VERSION ""

NS_ :

BS_:

BU_: PLEX

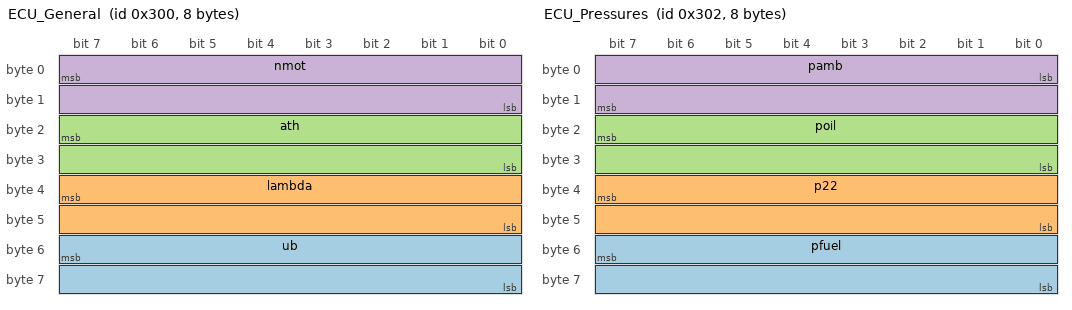
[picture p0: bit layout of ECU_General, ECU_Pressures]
BO_ 768 ECU_General: 8 MS6_Logger_CAN_Bus_1
 SG_ ub : 55|16@0- (0.01,0) [0|25.5] "V" Vector__XXX
 SG_ lambda : 39|16@0- (0.001,0) [0|5] "" Vector__XXX
 SG_ ath : 23|16@0- (0.1,0) [0|110] "%" Vector__XXX
 SG_ nmot : 7|16@0- (1,0) [0|20000] "rpm" Vector__XXX

BO_ 770 ECU_Pressures: 8 MS6_Logger_CAN_Bus_1
 SG_ pfuel : 55|16@0- (0.001,0) [0|10] "bar" Vector__XXX
 SG_ p22 : 39|16@0- (1,0) [0|5000] "mbar" Vector__XXX
 SG_ poil : 23|16@0- (0.001,0) [0|10] "bar" Vector__XXX
 SG_ pamb : 0|16@1+ (0.1,0) [0|2000] "mbar" Vector__XXX

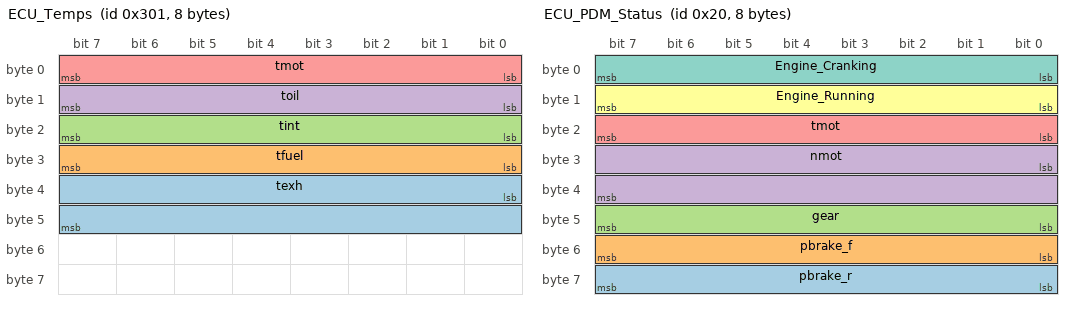
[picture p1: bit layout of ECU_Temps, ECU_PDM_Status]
BO_ 769 ECU_Temps: 8 MS6_Logger_CAN_Bus_1
 SG_ texh : 32|16@1+ (1,0) [0|1250] "°C" Vector__XXX
 SG_ tfuel : 31|8@0+ (1,0) [10|80] "°C" Vector__XXX
 SG_ tint : 23|8@0+ (1,0) [10|60] "°C" Vector__XXX
 SG_ toil : 15|8@0+ (1,0) [60|150] "°C" Vector__XXX
 SG_ tmot : 0|8@1+ (1,0) [40|120] "°C" Vector__XXX

BO_ 32 ECU_PDM_Status: 8 MS6_Logger_CAN_Bus_1
 SG_ pbrake_r : 56|8@1+ (1,0) [0|150] "bar" Vector__XXX
 SG_ pbrake_f : 48|8@1+ (1,0) [0|150] "bar" Vector__XXX
 SG_ gear : 40|8@1- (1,0) [-1|12] "" Vector__XXX
 SG_ nmot : 24|16@1+ (1,0) [0|20000] "rpm" Vector__XXX
 SG_ tmot : 16|8@1+ (1,0) [40|120] "°C" Vector__XXX
 SG_ Engine_Running : 8|8@1+ (1,0) [0|1] "" Vector__XXX
 SG_ Engine_Cranking : 0|8@1+ (1,0) [0|1] "" Vector__XXX

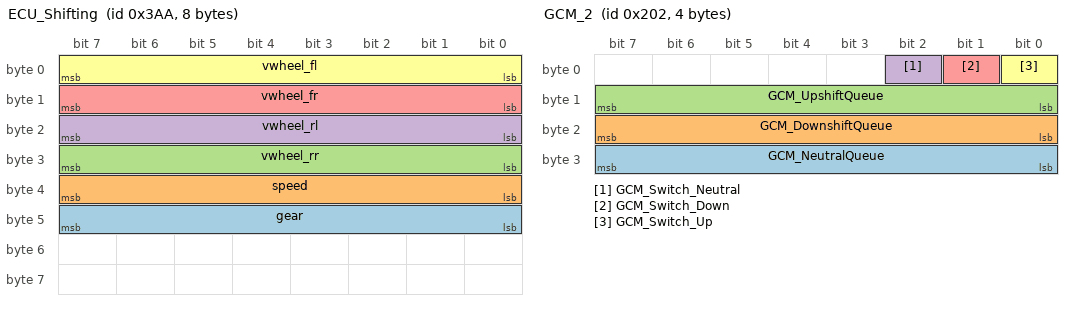
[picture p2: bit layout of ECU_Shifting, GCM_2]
BO_ 938 ECU_Shifting: 8 MS6_Logger_CAN_Bus_1
 SG_ gear : 40|8@1- (1,0) [-1|12] "" Vector__XXX
 SG_ speed : 32|8@1+ (1,0) [0|400] "km/h" Vector__XXX
 SG_ vwheel_rr : 24|8@1+ (1,0) [0|400] "km/h" Vector__XXX
 SG_ vwheel_rl : 16|8@1+ (1,0) [0|400] "km/h" Vector__XXX
 SG_ vwheel_fr : 8|8@1+ (1,0) [0|400] "km/h" Vector__XXX
 SG_ vwheel_fl : 0|8@1+ (1,0) [0|400] "km/h" Vector__XXX

BO_ 1023 ECU_Error: 8 MS6_Logger_CAN_Bus_1
 SG_ E_pbrake_f : 3|3@1+ (1,0) [0|255] "" Vector__XXX
 SG_ E_pbrake_r : 0|3@1+ (1,0) [0|255] "" Vector__XXX

BO_ 1967 IZZE_Brake_IR_Programming: 8 MS6_Logger_CAN_Bus_2

BO_ 256 GCM_MS6_Gear: 8 GCM
 SG_ GCM_Gear_MS6 : 0|8@1+ (0.5,-1.5) [0|0] "" Vector__XXX

BO_ 1552 GCM_MS6_Shift: 8 GCM
 SG_ GCM_Upshift_Bosch : 1|1@1+ (1,0) [0|0] "" Vector__XXX
 SG_ GCM_Downshift_Bosch : 0|1@1+ (1,0) [0|0] "" Vector__XXX

BO_ 514 GCM_2: 4 GCM
 SG_ GCM_NeutralQueue : 24|8@1+ (1,0) [0|0] "" Vector__XXX
 SG_ GCM_DownshiftQueue : 16|8@1+ (1,0) [0|0] "" Vector__XXX
 SG_ GCM_UpshiftQueue : 8|8@1+ (1,0) [0|0] "" Vector__XXX
 SG_ GCM_Switch_Neutral : 2|1@1+ (1,0) [0|0] "" Vector__XXX
 SG_ GCM_Switch_Down : 1|1@1+ (1,0) [0|0] "" Vector__XXX
 SG_ GCM_Switch_Up : 0|1@1+ (1,0) [0|0] "" Vector__XXX

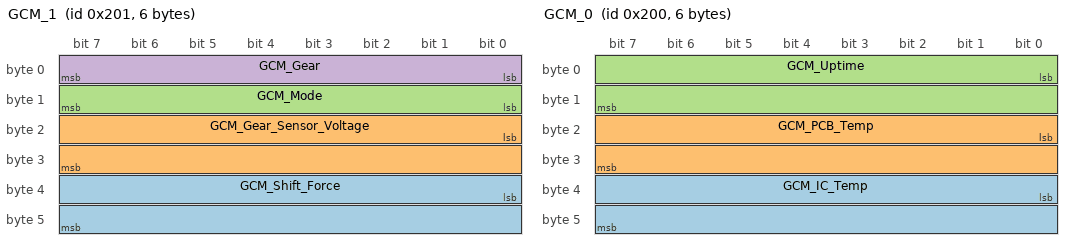
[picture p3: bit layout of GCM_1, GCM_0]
BO_ 513 GCM_1: 6 GCM
 SG_ GCM_Shift_Force : 32|16@1- (0.01,0) [0|0] "N" Vector__XXX
 SG_ GCM_Gear_Sensor_Voltage : 16|16@1+ (0.0001,0) [0|0] "V" Vector__XXX
 SG_ GCM_Mode : 8|8@1+ (1,0) [0|0] "" Vector__XXX
 SG_ GCM_Gear : 0|8@1+ (1,0) [0|0] "" Vector__XXX

BO_ 15 GCM_ERR: 4 GCM
 SG_ GCM_ERR_Code : 16|16@1+ (1,0) [0|0] "" Vector__XXX
 SG_ GCM_ERR_Origin_Node : 0|16@1+ (1,0) [0|0] "" Vector__XXX

BO_ 512 GCM_0: 6 GCM
 SG_ GCM_IC_Temp : 32|16@1- (0.005,0) [0|0] "C" Vector__XXX
 SG_ GCM_PCB_Temp : 16|16@1- (0.005,0) [0|0] "C" Vector__XXX
 SG_ GCM_Uptime : 0|16@1+ (1,0) [0|0] "s" Vector__XXX

BO_ 380 IMU_Z: 8 IMU
 SG_ IMU_Z_Accel : 32|16@1+ (0.0001274,-4.1746432) [0|0] "g" Vector__XXX

BO_ 376 IMU_X_Roll: 8 IMU
 SG_ IMU_X_Accel : 32|16@1+ (0.0001274,-4.1746432) [0|0] "g" Vector__XXX
 SG_ IMU_Roll_Rate : 0|16@1+ (0.005,-163.84) [0|0] "deg/s/s" Vector__XXX

BO_ 372 IMU_Y_Yaw: 8 IMU
 SG_ IMU_Y_Accel : 32|16@1+ (0.0001274,-4.1746432) [0|0] "g" Vector__XXX
 SG_ IMU_Yaw_Rate : 0|16@1+ (0.005,-163.84) [0|0] "deg/s" Vector__XXX

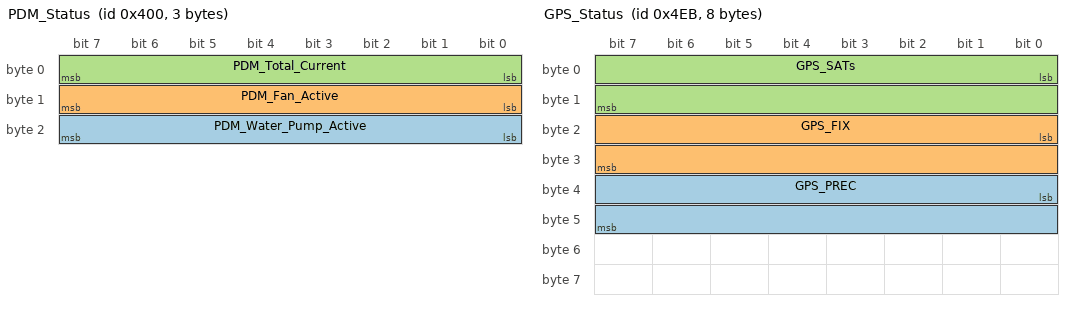
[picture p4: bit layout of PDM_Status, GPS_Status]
BO_ 1024 PDM_Status: 3 PDM
 SG_ PDM_Water_Pump_Active : 16|8@1- (1,0) [0|0] "" Vector__XXX
 SG_ PDM_Fan_Active : 8|8@1- (1,0) [0|0] "" Vector__XXX
 SG_ PDM_Total_Current : 0|8@1- (1,0) [0|127] "" Vector__XXX

BO_ 1259 GPS_Status: 8 PLEX
 SG_ GPS_PREC : 32|16@1- (0.1,0) [0|0] "m" Vector__XXX
 SG_ GPS_FIX : 16|16@1- (1,0) [0|0] "" Vector__XXX
 SG_ GPS_SATs : 0|16@1- (1,0) [0|0] "" Vector__XXX

BO_ 1258 GPS_Position: 8 PLEX
 SG_ GPS_Long : 32|32@1- (1e-07,0) [0|0] "deg" Vector__XXX
 SG_ GPS_Lat : 0|32@1- (1e-07,0) [0|0] "deg" Vector__XXX

CM_ BO_ 768 "RPM, Throttle Position, Lambda, Battery Voltage";
CM_ SG_ 768 ub "battery voltage";
CM_ SG_ 768 lambda "Lambda actual value";
CM_ SG_ 768 ath "throttle position";
CM_ SG_ 768 nmot "engine speed";
CM_ BO_ 770 "Ambient Pressure, Oil Pressure, Manifold Pressure, Fuel Pressure";
CM_ SG_ 770 pfuel "fuel pressure";
CM_ SG_ 770 p22 "intake manifold pressure downstream throttle";
CM_ SG_ 770 poil "oil pressure";
CM_ SG_ 770 pamb "ambient pressure";
CM_ BO_ 769 "Coolant Temp, Oil Temp, Manifold Temp, Fuel Temp, Exhaust Temp";
CM_ SG_ 769 texh "exhaust gas temperature";
CM_ SG_ 769 tfuel "fuel temperature";
CM_ SG_ 769 tint "intake air temperature";
CM_ SG_ 769 toil "oil temperature";
CM_ SG_ 769 tmot "engine temperature";
CM_ BO_ 32 "Engine_Cranking, Engine_Running, tmot, nmot, gear, pbrake_f, pbrake_r";
CM_ SG_ 32 pbrake_r "brake pressure rear";
CM_ SG_ 32 pbrake_f "brake pressure front ";
CM_ SG_ 32 gear "selected gear";
CM_ SG_ 32 nmot "engine speed";
CM_ SG_ 32 tmot "engine temperature";
CM_ SG_ 32 Engine_Running "Returns true, if (nmot > 0)";
CM_ SG_ 32 Engine_Cranking "Returns true, if (1 <= nmot <= 1000)";
CM_ BO_ 938 "FL/FR/RL/RR Wheel Speed, Ground Speed, Gear";
CM_ SG_ 938 gear "selected gear";
CM_ SG_ 938 speed "car speed";
CM_ SG_ 938 vwheel_rr "wheel speed rear right";
CM_ SG_ 938 vwheel_rl "wheel speed rear left";
CM_ SG_ 938 vwheel_fr "wheel speed front right";
CM_ SG_ 938 vwheel_fl "wheel speed front left";
CM_ BO_ 1023 "Critical error codes";
CM_ SG_ 1023 E_pbrake_f "error state brake pressure front";
CM_ SG_ 1023 E_pbrake_r "error state brake pressure rear";
CM_ BO_ 1967 "Programming message template for IZZE Brake IR sensor";
CM_ BO_ 1552 "Upshift/downshift ignition cut triggers for the MS6";
CM_ BO_ 514 "Paddles, Shift Queues";
CM_ BO_ 513 "Gear, Gear Sensor Voltage, Mode, Shift force";
CM_ BO_ 15 "Error flags for IM boards";
CM_ BO_ 512 "Uptime, Temperatures";
CM_ BO_ 380 "Z accel";
CM_ BO_ 376 "Roll rate, X accel";
CM_ BO_ 372 "Yaw rate, Y accel";
